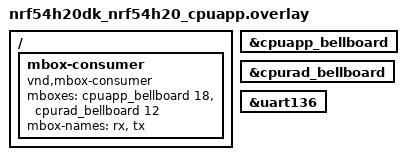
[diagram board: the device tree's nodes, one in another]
/*
 * Copyright 2024 Nordic Semiconductor ASA
 * SPDX-License-Identifier: Apache-2.0
 */

/ {
	mbox-consumer {
		compatible = "vnd,mbox-consumer";
		mboxes = <&cpuapp_bellboard 18>, <&cpurad_bellboard 12>;
		mbox-names = "rx", "tx";
	};
};

&cpuapp_bellboard {
	status = "okay";
};

&cpurad_bellboard {
	status = "okay";
};

&uart136 {
	/delete-property/ hw-flow-control;
};
